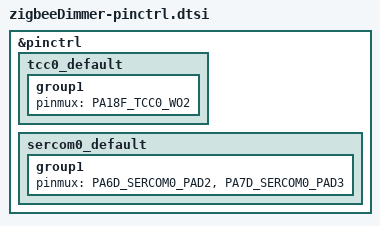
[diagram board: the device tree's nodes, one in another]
/*
 * Copyright (c) 2021 Argentum Systems Ltd.
 *
 * SPDX-License-Identifier: Apache-2.0
 */

#include <dt-bindings/pinctrl/samr30e-pinctrl.h>

&pinctrl {
	tcc0_default: tcc0_default {
		group1 {
			//pinmux = <PA19F_TCC0_WO3>;
			pinmux = <PA18F_TCC0_WO2>;
		};
	};

	sercom0_default: sercom0_default {
		group1 {
			pinmux = <PA6D_SERCOM0_PAD2>,
				 <PA7D_SERCOM0_PAD3>;
		};
	};
};
